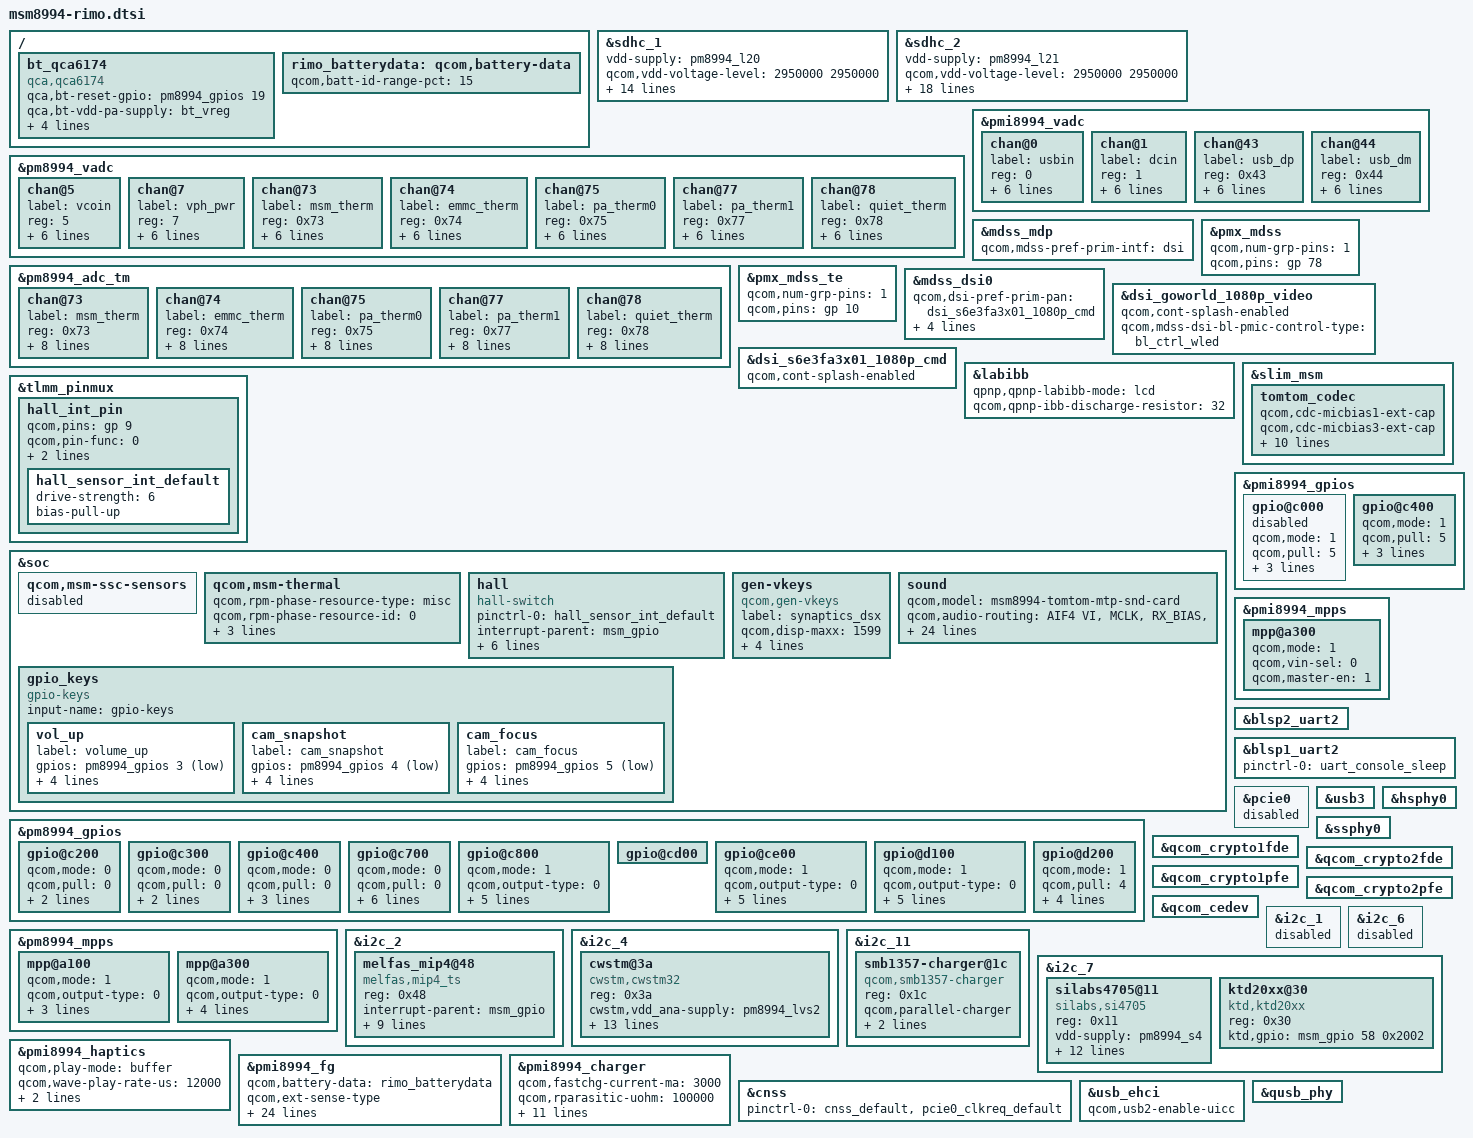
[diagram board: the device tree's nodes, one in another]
/* Copyright (c) 2014-2015, The Linux Foundation. All rights reserved.
 *
 * This program is free software; you can redistribute it and/or modify
 * it under the terms of the GNU General Public License version 2 and
 * only version 2 as published by the Free Software Foundation.
 *
 * This program is distributed in the hope that it will be useful,
 * but WITHOUT ANY WARRANTY; without even the implied warranty of
 * MERCHANTABILITY or FITNESS FOR A PARTICULAR PURPOSE.  See the
 * GNU General Public License for more details.
 */

#include "msm8994-pinctrl.dtsi"
#include "msm8994-camera-sensor-rimo.dtsi"

/ {
	bt_qca6174 {
		compatible = "qca,qca6174";
		qca,bt-reset-gpio = <&pm8994_gpios 19 0>; /* BT_EN */
		qca,bt-vdd-pa-supply = <&bt_vreg>;
		qca,bt-vdd-io-supply = <&pm8994_s4>;
		qca,bt-vdd-xtal-supply = <&pm8994_l30>;
		qca,bt-vdd-io-voltage-level = <1800000 1800000>;
		qca,bt-vdd-xtal-voltage-level = <1800000 1800000>;
	};
};

&sdhc_1 {
	vdd-supply = <&pm8994_l20>;
	qcom,vdd-voltage-level = <2950000 2950000>;
	qcom,vdd-current-level = <200 570000>;

	vdd-io-supply = <&pm8994_s4>;
	qcom,vdd-io-always-on;
	qcom,vdd-io-voltage-level = <1800000 1800000>;
	qcom,vdd-io-current-level = <200 325000>;

	pinctrl-names = "active", "sleep";
	pinctrl-0 = <&sdc1_clk_on &sdc1_cmd_on &sdc1_data_on &sdc1_rclk_on>;
	pinctrl-1 = <&sdc1_clk_off &sdc1_cmd_off &sdc1_data_off &sdc1_rclk_off>;

	qcom,nonremovable;

	qcom,clk-rates = <400000 20000000 25000000 50000000 100000000 192000000 384000000>;
	qcom,bus-speed-mode = "HS400_1p8v", "HS200_1p8v", "DDR_1p8v";
	status = "ok";
};

&sdhc_2 {
	vdd-supply = <&pm8994_l21>;
	qcom,vdd-voltage-level = <2950000 2950000>;
	qcom,vdd-current-level = <200 800000>;

	vdd-io-supply = <&pm8994_l13>;
	qcom,vdd-io-voltage-level = <1800000 2950000>;
	qcom,vdd-io-current-level = <200 22000>;

	#address-cells = <0>;
	interrupt-parent = <&sdhc_2>;
	interrupts = <0 1 2>;
	#interrupt-cells = <1>;
	interrupt-map-mask = <0xffffffff>;
	interrupt-map = <0 &intc 0 125 0
			1 &intc 0 221 0
			2 &pm8994_gpios 8 0x3>;
	interrupt-names = "hc_irq", "pwr_irq", "status_irq";
	cd-gpios = <&pm8994_gpios 8 0x0>;

	pinctrl-names = "active", "sleep";
	pinctrl-0 = <&sdc2_clk_on &sdc2_cmd_on &sdc2_data_on>;
	pinctrl-1 = <&sdc2_clk_off &sdc2_cmd_off &sdc2_data_off>;

	qcom,clk-rates = <400000 20000000 25000000 50000000 100000000 200000000>;
	qcom,bus-speed-mode = "SDR12", "SDR25", "SDR50", "DDR50", "SDR104";
	status = "ok";
};

/*
&ufsphy1 {
	status = "ok";
};

&ufs1 {
	status = "ok";
};
*/

&pm8994_vadc {
	chan@5 {
		label = "vcoin";
		reg = <5>;
		qcom,decimation = <0>;
		qcom,pre-div-channel-scaling = <1>;
		qcom,calibration-type = "absolute";
		qcom,scale-function = <0>;
		qcom,hw-settle-time = <0>;
		qcom,fast-avg-setup = <0>;
	};

	chan@7 {
		label = "vph_pwr";
		reg = <7>;
		qcom,decimation = <0>;
		qcom,pre-div-channel-scaling = <1>;
		qcom,calibration-type = "absolute";
		qcom,scale-function = <0>;
		qcom,hw-settle-time = <0>;
		qcom,fast-avg-setup = <0>;
	};

	chan@73 {
		label = "msm_therm";
		reg = <0x73>;
		qcom,decimation = <0>;
		qcom,pre-div-channel-scaling = <0>;
		qcom,calibration-type = "ratiometric";
		qcom,scale-function = <2>;
		qcom,hw-settle-time = <2>;
		qcom,fast-avg-setup = <0>;
	};

	chan@74 {
		label = "emmc_therm";
		reg = <0x74>;
		qcom,decimation = <0>;
		qcom,pre-div-channel-scaling = <0>;
		qcom,calibration-type = "ratiometric";
		qcom,scale-function = <2>;
		qcom,hw-settle-time = <2>;
		qcom,fast-avg-setup = <0>;
	};

	chan@75 {
		label = "pa_therm0";
		reg = <0x75>;
		qcom,decimation = <0>;
		qcom,pre-div-channel-scaling = <0>;
		qcom,calibration-type = "ratiometric";
		qcom,scale-function = <2>;
		qcom,hw-settle-time = <2>;
		qcom,fast-avg-setup = <0>;
	};

	chan@77 {
		label = "pa_therm1";
		reg = <0x77>;
		qcom,decimation = <0>;
		qcom,pre-div-channel-scaling = <0>;
		qcom,calibration-type = "ratiometric";
		qcom,scale-function = <2>;
		qcom,hw-settle-time = <2>;
		qcom,fast-avg-setup = <0>;
	};

	chan@78 {
		label = "quiet_therm";
		reg = <0x78>;
		qcom,decimation = <0>;
		qcom,pre-div-channel-scaling = <0>;
		qcom,calibration-type = "ratiometric";
		qcom,scale-function = <2>;
		qcom,hw-settle-time = <2>;
		qcom,fast-avg-setup = <0>;
	};
};

&pm8994_adc_tm {
	chan@73 {
		label = "msm_therm";
		reg = <0x73>;
		qcom,decimation = <0>;
		qcom,pre-div-channel-scaling = <0>;
		qcom,calibration-type = "ratiometric";
		qcom,scale-function = <2>;
		qcom,hw-settle-time = <2>;
		qcom,fast-avg-setup = <0>;
		qcom,btm-channel-number = <0x48>;
		qcom,thermal-node;
	};

	chan@74 {
		label = "emmc_therm";
		reg = <0x74>;
		qcom,decimation = <0>;
		qcom,pre-div-channel-scaling = <0>;
		qcom,calibration-type = "ratiometric";
		qcom,scale-function = <2>;
		qcom,hw-settle-time = <2>;
		qcom,fast-avg-setup = <0>;
		qcom,btm-channel-number = <0x68>;
		qcom,thermal-node;
	};

	chan@75 {
		label = "pa_therm0";
		reg = <0x75>;
		qcom,decimation = <0>;
		qcom,pre-div-channel-scaling = <0>;
		qcom,calibration-type = "ratiometric";
		qcom,scale-function = <2>;
		qcom,hw-settle-time = <2>;
		qcom,fast-avg-setup = <0>;
		qcom,btm-channel-number = <0x70>;
		qcom,thermal-node;
	};

	chan@77 {
		label = "pa_therm1";
		reg = <0x77>;
		qcom,decimation = <0>;
		qcom,pre-div-channel-scaling = <0>;
		qcom,calibration-type = "ratiometric";
		qcom,scale-function = <2>;
		qcom,hw-settle-time = <2>;
		qcom,fast-avg-setup = <0>;
		qcom,btm-channel-number = <0x78>;
		qcom,thermal-node;
	};

	chan@78 {
		label = "quiet_therm";
		reg = <0x78>;
		qcom,decimation = <0>;
		qcom,pre-div-channel-scaling = <0>;
		qcom,calibration-type = "ratiometric";
		qcom,scale-function = <2>;
		qcom,hw-settle-time = <2>;
		qcom,fast-avg-setup = <0>;
		qcom,btm-channel-number = <0x80>;
		qcom,thermal-node;
	};
};

&pmi8994_vadc {
	chan@0 {
		label = "usbin";
		reg = <0>;
		qcom,decimation = <0>;
		qcom,pre-div-channel-scaling = <4>;
		qcom,calibration-type = "absolute";
		qcom,scale-function = <0>;
		qcom,hw-settle-time = <0>;
		qcom,fast-avg-setup = <0>;
	};

	chan@1 {
		label = "dcin";
		reg = <1>;
		qcom,decimation = <0>;
		qcom,pre-div-channel-scaling = <4>;
		qcom,calibration-type = "absolute";
		qcom,scale-function = <0>;
		qcom,hw-settle-time = <0>;
		qcom,fast-avg-setup = <0>;
	};

	chan@43 {
		label = "usb_dp";
		reg = <0x43>;
		qcom,decimation = <0>;
		qcom,pre-div-channel-scaling = <1>;
		qcom,calibration-type = "absolute";
		qcom,scale-function = <0>;
		qcom,hw-settle-time = <0>;
		qcom,fast-avg-setup = <0>;
	};

	chan@44 {
		label = "usb_dm";
		reg = <0x44>;
		qcom,decimation = <0>;
		qcom,pre-div-channel-scaling = <1>;
		qcom,calibration-type = "absolute";
		qcom,scale-function = <0>;
		qcom,hw-settle-time = <0>;
		qcom,fast-avg-setup = <0>;
	};
};

#include "dsi-panel-goworld-1080p-video.dtsi"
#include "dsi-panel-s6e3fa3x01_1080p_cmd.dtsi"

&mdss_mdp {
	qcom,mdss-pref-prim-intf = "dsi";
};

&pmx_mdss {
	qcom,num-grp-pins = <1>;
	qcom,pins = <&gp 78>;
};

&pmx_mdss_te {
	qcom,num-grp-pins = <1>;
	qcom,pins = <&gp 10>;
};


&mdss_dsi0 {
   qcom,dsi-pref-prim-pan = <&dsi_s6e3fa3x01_1080p_cmd>;
   pinctrl-names = "mdss_default", "mdss_sleep";
   pinctrl-0 = <&mdss_dsi_active &mdss_te_active>;
   pinctrl-1 = <&mdss_dsi_suspend &mdss_te_suspend>;
   qcom,platform-te-gpio = <&msm_gpio 10 0>;
   qcom,platform-reset-gpio = <&msm_gpio 78 0>;
};
/*
&mdss_dsi1 {
	qcom,dsi-pref-prim-pan = <&dsi_dual_sharp_video_1>;
};
*/
&dsi_goworld_1080p_video {
   qcom,cont-splash-enabled;
   qcom,mdss-dsi-bl-pmic-control-type = "bl_ctrl_wled";
};

&dsi_s6e3fa3x01_1080p_cmd {
   qcom,cont-splash-enabled;
};


&labibb {
	status = "ok";
	qpnp,qpnp-labibb-mode = "lcd";
	qcom,qpnp-ibb-discharge-resistor = <32>;
};

&tlmm_pinmux {
   hall_int_pin {
      qcom,pins = <&gp 9>;
      qcom,pin-func = <0>;
      qcom,num-grp-pins = <1>;
      label = "hall-irq";
      hall_sensor_int_default: hall_sensor_int_default {
         drive-strength = <6>;
         bias-pull-up;
      };
   };
};

&soc {
   qcom,msm-ssc-sensors {
	   status = "disabled";
   };
   
   qcom,msm-thermal {
      qcom,rpm-phase-resource-type = "misc";
      qcom,rpm-phase-resource-id = <0>;
      qcom,cx-phase-resource-key = "tmpc";
      qcom,cx-phase-hot-crit-temp = <85>;
      qcom,cx-phase-hot-crit-temp-hyst = <15>;
   };

   hall {
      compatible = "hall-switch";
      pinctrl-names = "default";
      pinctrl-0 = <&hall_sensor_int_default>;
      interrupt-parent = <&msm_gpio>;
      interrupts = <9 0x2003>;
      vddio-supply = <&pm8994_l18>;
      linux,gpio-int = <&msm_gpio 9 0x1>;
      linux,wakeup;
      linux,min-uv = <2850000>;
      linux,max-uv = <2850000>;
   };

	gen-vkeys {
		compatible = "qcom,gen-vkeys";
		label = "synaptics_dsx";
		qcom,disp-maxx = <1599>;
		qcom,disp-maxy = <2559>;
		qcom,panel-maxx = <1599>;
		qcom,panel-maxy = <2703>;
		qcom,key-codes = <158 139 102 217>;
	};
	
   gpio_keys {
		compatible = "gpio-keys";
		input-name = "gpio-keys";

		vol_up {
			label = "volume_up";
			gpios = <&pm8994_gpios 3 0x1>;
			linux,input-type = <1>;
			linux,code = <115>;
			gpio-key,wakeup;
			debounce-interval = <15>;
		};
		
      cam_snapshot {
			label = "cam_snapshot";
			gpios = <&pm8994_gpios 4 0x1>;
			linux,input-type = <1>;
			linux,code = <766>;
			gpio-key,wakeup;
			debounce-interval = <15>;
		};

		cam_focus {
			label = "cam_focus";
			gpios = <&pm8994_gpios 5 0x1>;
			linux,input-type = <1>;
			linux,code = <528>;
			gpio-key,wakeup;
			debounce-interval = <15>;
		};
	};

	sound {
		qcom,model = "msm8994-tomtom-mtp-snd-card";

       qcom,audio-routing =
          "AIF4 VI", "MCLK",
          "RX_BIAS", "MCLK",
          "LDO_H", "MCLK",
          "MADINPUT", "MCLK",
          "ultrasound amp", "LINEOUT1",
          "ultrasound amp", "LINEOUT3",
          "AMIC1", "MIC BIAS1 External",
          "MIC BIAS1 External", "Handset Mic",
          "AMIC2", "MIC BIAS2 External",
          "MIC BIAS2 External", "Headset Mic",
          "AMIC3", "MIC BIAS3 External",
          "MIC BIAS3 External", "ANC Mic",
          "AMIC4", "MIC BIAS4 External",
          "MIC BIAS4 External", "Rearup Mic",
          "AMIC5", "MIC BIAS4 External",
          "MIC BIAS4 External", "Reardown Mic5",
          "AMIC6", "MIC BIAS4 External",
          "MIC BIAS4 External", "Analog Mic6",
          "DMIC1", "MIC BIAS1 External",
          "MIC BIAS1 External", "Digital Mic1",
          "DMIC2", "MIC BIAS1 External",
          "MIC BIAS1 External", "Digital Mic2",
          "DMIC3", "MIC BIAS3 External",
          "MIC BIAS3 External", "Digital Mic3",
          "DMIC4", "MIC BIAS3 External",
          "MIC BIAS3 External", "Digital Mic4",
          "DMIC5", "MIC BIAS4 External",
          "MIC BIAS4 External", "Digital Mic5",
          "DMIC6", "MIC BIAS4 External",
          "MIC BIAS4 External", "Digital Mic6";
/*
		qcom,us-euro-gpios = <&pm8994_mpps 2 0>;
*/
		qcom,cdc-micbias2-headset-only;
		qcom,mbhc-audio-jack-type = "4-pole-jack";
		qcom,ext-ult-spk-amp-gpio = <&pmi8994_gpios 1 0>;
/*
		qcom,hdmi-audio-rx;
		asoc-codec = <&stub_codec>, <&hdmi_audio>;
		asoc-codec-names = "msm-stub-codec.1", "msm-hdmi-audio-codec-rx";
*/
	};
};

&pm8994_gpios {
	gpio@c200 { /* GPIO 3 */
		qcom,mode = <0>;
		qcom,pull = <0>;
		qcom,vin-sel = <2>;
		qcom,src-sel = <0>;
		status = "okay";
	};

	gpio@c300 { /* GPIO 4 */
		qcom,mode = <0>;
		qcom,pull = <0>;
		qcom,vin-sel = <2>;
		qcom,src-sel = <0>;
		status = "okay";
	};

	gpio@c400 { /* GPIO 5 */
		qcom,mode = <0>;
		qcom,pull = <0>;
		qcom,vin-sel = <2>;
		qcom,src-sel = <0>;
      qcom,out-strength = <1>;
		status = "okay";
	};

	gpio@c700 { /* GPIO 8 */
		qcom,mode = <0>;                /* Digital in */
		qcom,pull = <0>;                /* PULL up 30uA */
		qcom,output-type = <0>;         /* CMOS logic */
		qcom,invert = <0>;              /* Output high */
		qcom,vin-sel = <2>;             /* Logical 1 voltage value 1.8v */
		qcom,src-sel = <0>;             /* Constant */
		qcom,out-strength = <1>;        /* Low drive strength */
		qcom,master-en = <1>;           /* Enable GPIO */
		status = "okay";
	};

	gpio@c800 { /* GPIO 9 */
		qcom,mode = <1>;		/* Digital output */
		qcom,output-type = <0>;		/* CMOS logic */
		qcom,invert = <1>;		/* Output high */
		qcom,vin-sel = <0>;		/* VPH_PWR */
		qcom,src-sel = <0>;		/* Constant */
		qcom,out-strength = <1>;	/* High drive strength */
		qcom,master-en = <1>;		/* Enable GPIO */
		status = "okay";
	};

	gpio@cd00 { /* GPIO 14 */
		status = "okay";
	};

	gpio@ce00 { /* GPIO 15 */
		qcom,mode = <1>;
		qcom,output-type = <0>;
		qcom,pull = <5>;
		qcom,vin-sel = <2>;
		qcom,out-strength = <1>;
		qcom,src-sel = <2>;
		qcom,master-en = <1>;
		status = "okay";
	};

	gpio@d100 { /* GPIO 18 */
		qcom,mode = <1>;		/* Digital output */
		qcom,output-type = <0>;		/* CMOS logic */
		qcom,invert = <0>;		/* Output low initially */
		qcom,vin-sel = <2>;		/* VIN 2 */
		qcom,src-sel = <3>;		/* Function 2 */
		qcom,out-strength = <2>;	/* Medium */
		qcom,master-en = <1>;		/* Enable GPIO */
		status = "okay";
	};

	gpio@d200 { /* GPIO 19 */
		qcom,mode = <1>;         /* Digital output*/
		qcom,pull = <4>;         /* Pulldown 10uA */
		qcom,vin-sel = <2>;      /* VIN2 */
		qcom,src-sel = <0>;      /* GPIO */
		qcom,invert = <0>;       /* Invert */
		qcom,master-en = <1>;    /* Enable GPIO */
		status = "okay";
	};
};

&pm8994_mpps {
	mpp@a100 { /* MPP 2 */
		qcom,mode = <1>;		/* Digital output */
		qcom,output-type = <0>;		/* CMOS logic */
		qcom,vin-sel = <2>;		/* S4 1.8V */
		qcom,src-sel = <0>;		/* Constant */
		qcom,master-en = <1>;		/* Enable GPIO */
		status = "okay";
	};

	mpp@a300 { /* MPP 4 */
		/* HDMI_5v_vreg regulator enable */
		qcom,mode = <1>;		/* Digital output */
		qcom,output-type = <0>;		/* CMOS logic */
		qcom,vin-sel = <2>;		/* S4 1.8V */
		qcom,src-sel = <0>;		/* Constant */
		qcom,master-en = <1>;		/* Enable GPIO */
		qcom,invert = <0>;
		status = "okay";
	};
};

&slim_msm {
	tomtom_codec {
		qcom,cdc-micbias1-ext-cap;
		qcom,cdc-micbias3-ext-cap;
		qcom,cdc-micbias4-ext-cap;
		cdc-vdd-spkdrv-supply = <&pmi8994_boost_pin_ctrl>;
		qcom,cdc-vdd-spkdrv-voltage = <5000000 5000000>;
		qcom,cdc-vdd-spkdrv-current = <600000>;

		cdc-vdd-spkdrv-2-supply = <&pmi8994_boost_pin_ctrl>;
		qcom,cdc-vdd-spkdrv-2-voltage = <5000000 5000000>;
		qcom,cdc-vdd-spkdrv-2-current = <600000>;

		qcom,cdc-on-demand-supplies = "cdc-vdd-spkdrv",
					      "cdc-vdd-spkdrv-2";
	};
};

&pmi8994_gpios {
	gpio@c000 {	/* GPIO 1  Ultrasound PA EN */
		qcom,mode = <1>;	/* DIGITAL OUT */
		qcom,pull = <5>;	/* No Pull */
		qcom,vin-sel = <2>;	/* 1.8 */
		qcom,src-sel = <0>;	/* CONSTANT */
		qcom,master-en = <1>;	/* ENABLE GPIO */
		status = "disabled";
	};

	gpio@c400 {	/* GPIO 5  OTG SWITCH EN */
		qcom,mode = <1>;	/* DIGITAL OUT */
		qcom,pull = <5>;	/* No Pull */
		qcom,vin-sel = <2>;	/* 1.8 */
		qcom,src-sel = <0>;	/* GPIO */
		qcom,master-en = <1>;	/* ENABLE GPIO */
		status = "okay";
	};
};

&pmi8994_mpps {
	mpp@a300 { /* MPP 4 */
		/* WLED FET */
		qcom,mode = <1>;	/* DIGITAL OUT */
		qcom,vin-sel = <0>;	/* VIN0 */
		qcom,master-en = <1>;
		status = "okay";
	};
};

&blsp2_uart2 {
	status = "ok";
};

&blsp1_uart2 {
	status= "ok";
	 pinctrl-names = "default";
	 pinctrl-0 = <&uart_console_sleep>;
};


&pcie0 {
	status = "disabled";
};

/*
&pcie1 {
	status = "disabled";
};
*/
&usb3 {
	status = "ok";
};

&hsphy0 {
	status = "ok";
};

&ssphy0 {
	status = "ok";
};

&qcom_crypto1fde {
	status = "okay";
};

&qcom_crypto2fde {
	status = "okay";
};

&qcom_crypto1pfe {
	status = "okay";
};

&qcom_crypto2pfe {
	status = "okay";
};

&qcom_cedev {
	status = "okay";
};

&i2c_1 {
	status = "disabled";
};

&i2c_2 {
   melfas_mip4@48 {
      compatible = "melfas,mip4_ts";
      reg = <0x48>;
      interrupt-parent = <&msm_gpio>;
      interrupts = <61 0x2>;
      pinctrl-names = "default";
      mip4_ts,fw_name = "melfas/melfas.bin";
      pinctrl-0 = <&melfas_int_default>;
      mip4_ts,irq-gpio = <&msm_gpio 61 0x00>;
      mip4_ts,reset-gpio = <&msm_gpio 60 0x00>;
      mip4_ts,vdd-supply = <&msm_gpio 31 0x00>;
      mip4_ts,i2c-pull-up = <1>;
      mip4_ts,max_x = <1080>;
      mip4_ts,max_y = <1920>;
   };
};

&i2c_4 {
   cwstm@3a {
      compatible = "cwstm,cwstm32";
      reg = <0x3a>;
      cwstm,vdd_ana-supply = <&pm8994_lvs2>;
      cwstm,vcc_i2c-supply = <&pm8994_lvs2>;
      cwstm,vcc_sensors-supply = <&pm8994_l18>;
      pinctrl-names = "cwstm_default", "cwstm_sleep";
      pinctrl-0 = <&cw_int_default &cw_wakeup_default &cw_reset_default &cw_bootmode_default>;
      pinctrl-1 = <&cw_int_sleep &cw_wakeup_sleep &cw_reset_sleep &cw_bootmode_sleep>;
      interrupt-parent = <&msm_gpio>;
      interrupts = <53 0x2>;
      cwstm,fw-name = "cw_fw.bin";
      cwstm,irq-gpio = <&msm_gpio 53 0>;
      cwstm,wakeup-gpio = <&msm_gpio 54 0>;
      cwstm,reset-gpio = <&msm_gpio 55 0>;
      cwstm,boot-gpio = <&msm_gpio 25 0>;
   };
};

&i2c_11 {
	smb1357-charger@1c {
		compatible = "qcom,smb1357-charger";
		reg = <0x1c>;
		qcom,parallel-charger;
		qcom,float-voltage-mv = <4350>;
		qcom,recharge-thresh-mv = <100>;
	};
};

&i2c_6 {
	status = "disabled";
};

&i2c_7 {
   status = "ok";
   silabs4705@11 { /* SiLabs FM chip, slave id 0x11*/
		status = "ok";
		compatible = "silabs,si4705";
		reg = <0x11>;
		vdd-supply = <&pm8994_s4>;
		silabs,vdd-supply-voltage = <1800000 1800000>;
		va-supply = <&pm8994_l19>;
		silabs,va-supply-voltage = <2800000 2800000>;
		pinctrl-names = "pmx_fm_active","pmx_fm_suspend";
		pinctrl-0 = <&fm_int_active &fm_status_int_active &fm_rst_active>;
		pinctrl-1 = <&fm_int_suspend &fm_status_int_suspend &fm_rst_suspend>;
		silabs,reset-gpio = <&msm_gpio 62 0>;
		silabs,int-gpio = <&msm_gpio 63 0>;
		//silabs,status-gpio = <&msm_gpio 11 0>;
		#address-cells = <0>;
      interrupt-parent = <&msm_gpio>;
      interrupts = <63 2>;
      interrupt-names = "silabs_fm_int";
      clocks = <&clock_rpm clk_bb_clk2_pin>;
      clock-names = "ref_clk";
   };

   ktd20xx@30 {
      compatible = "ktd,ktd20xx";
      reg = <0x30>;
      ktd,gpio = <&msm_gpio 58 0x2002>;
   };
};

&pmi8994_haptics {
	status = "okay";
   qcom,play-mode = "buffer";
   qcom,wave-play-rate-us = <12000>;
   qcom,actuator-type = "erm";
   qcom,vmax-mv = <3300>;
};

/{
	rimo_batterydata: qcom,battery-data {
		qcom,batt-id-range-pct = <15>;
      #include "batterydata-tron5011-3000mah.dtsi"
	};
};

&pmi8994_fg {
	qcom,battery-data = <&rimo_batterydata>;
	qcom,ext-sense-type;
   qcom,thermal-coefficients = [c2 86 bb 50 cf 37];
   qcom,warm-bat-decidegc = <450>;
   qcom,cool-bat-decidegc = <100>;
   qcom,hot-bat-decidegc = <550>;
   qcom,cold-bat-decidegc = <0>;
   qcom,resume-soc = <99>;
   qcom,bcl-lm-threshold-ma = <127>;
   qcom,bcl-mh-threshold-ma = <405>;
   qcom,fg-iterm-ma = <360>;
   qcom,fg-chg-iterm-ma = <200>;
   qcom,irq-volt-empty-mv = <3100>;
   qcom,fg-cutoff-voltage-mv = <3500>;
   qcom,vbat-estimate-diff-mv = <200>;
   qcom,fg-delta-soc = <1>;
   qcom,fg-soc-max = <90>;
   qcom,fg-soc-min = <5>;
   qcom,fg-vbatt-low-threshold = <3600>;
   qcom,cycle-counter-en;
   qcom,cycle-counter-low-soc = <15>;
   qcom,cycle-counter-high-soc = <85>;
   qcom,capacity-learning-on;
   qcom,cl-max-start-capacity = <50>;
   qcom,fg-cc-cv-threshold-mv = <4340>;
   qcom,fg-ibatt-standby-ma = <20>;
   status = "okay";
};

&pmi8994_charger {
   qcom,fastchg-current-ma = <3000>;
   qcom,rparasitic-uohm = <100000>;
   qcom,bms-psy-name = "bms";
   qcom,thermal-mitigation = <2000 1500 700 0>;
   qcom,charge-unknown-battery;
   qcom,bmd-pin-src = "bpd_thm";
   qcom,bmd-algo-disabled;
   qcom,force-aicl-rerun;
   jeita-temp-hard-limit = <1>;
   qcom,fastchg-current-comp-warm = <1200>;/*250,700,900,1200*/
   qcom,float-voltage-comp-warm = <13>; /*4.10 V*/
   qcom,fastchg-current-comp-cool = <900>;
   qcom,float-voltage-comp-cool = <0>;
   status = "okay";
};

/*
&pmi8994_charger {
	qcom,dc-psy-type = "Wipower";
	qcom,dcin-vadc = <&pmi8994_vadc>;
	qcom,wipower-default-ilim-map = <4000000 20000000 550 700 300>;
	qcom,wipower-pt-ilim-map = <4000000 7140000 550 700 300>,
					<7140000 8140000 550 700 300>,
					<8140000 9140000 500 700 300>,
					<9140000 9950000 500 700 300>;
	qcom,wipower-div2-ilim-map = <4000000 4820000 550 700 300>,
					<4820000 5820000 550 700 300>,
					<5820000 6820000 550 650 650>,
					<6820000 7820000 550 700 600>,
					<7820000 8500000 550 700 550>;
};
*/

&cnss {
	pinctrl-names = "default";
	pinctrl-0 = <&cnss_default &pcie0_clkreq_default>;
};

&usb_ehci {
	status = "ok";
	qcom,usb2-enable-uicc;
};

&qusb_phy {
	status = "ok";
};
